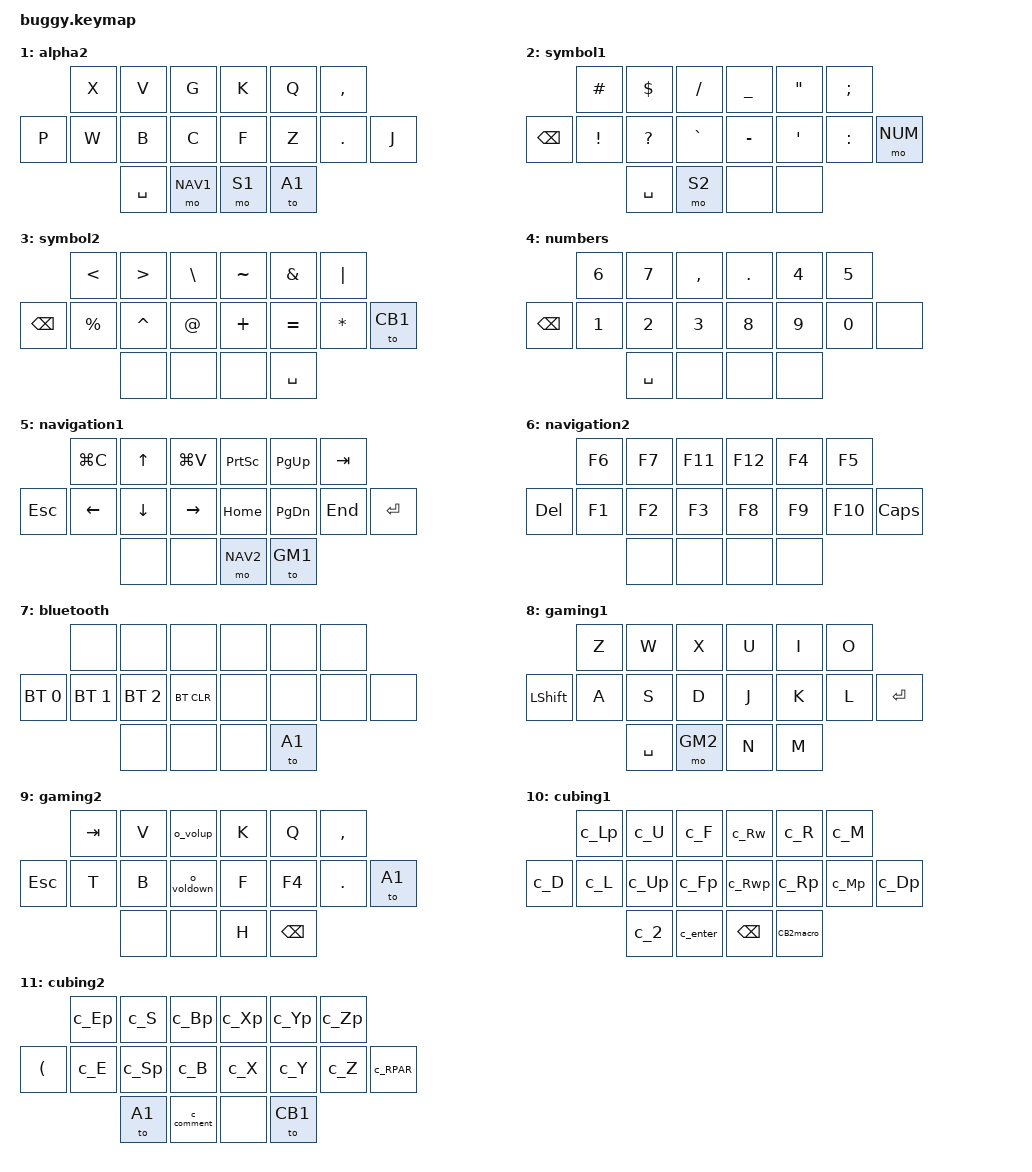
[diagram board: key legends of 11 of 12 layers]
#include <behaviors.dtsi>
#include <dt-bindings/zmk/keys.h>
#include <dt-bindings/zmk/bt.h>

// Homerow Mods
#define hrml(k1,k2,k3,k4) &ht LCTRL k1  &ht LALT k2  &ht LSHFT k3  &ht LCMD k4
#define hrmr(k1,k2,k3,k4) &ht RCMD k1  &ht RSHFT k2  &ht RALT k3  &ht RCTRL k4

#define A1 0
#define A2 1
#define S1 2
#define S2 3
#define NUM 4
#define NAV1 5
#define NAV2 6
#define BT 7
#define GM1 8
#define GM2 9
#define CB1 10
#define CB2 11

//        0  1  2     3  4  5
//     6  7  8  9     10 11 12 13

//           14 15    16 17

/ {
    combos {
        compatible = "zmk,combos";
// a1
        rlcombo {
            timeout-ms = <20>;
            key-positions = <7 0>;
            bindings = <&rlmacro>;
            layers = <A1>;
        };
        tdcombo {
            timeout-ms = <20>;
            key-positions = <8 1>;
            bindings = <&tdmacro>;
            layers = <A1>;
        };
        yscombo {
            timeout-ms = <20>;
            key-positions = <9 2>;
            bindings = <&ysmacro>;
            layers = <A1>;
        };
        hmcombo {
            timeout-ms = <20>;
            key-positions = <10 3>;
            bindings = <&hmmacro>;
            layers = <A1>;
        };
        oacombo {
            timeout-ms = <20>;
            key-positions = <11 4>;
            bindings = <&oamacro>;
            layers = <A1>;
        };
        uicombo {
            timeout-ms = <20>;
            key-positions = <12 5>;
            bindings = <&uimacro>;
            layers = <A1>;
        };
// a2
        ckcombo {
            timeout-ms = <20>;
            key-positions = <9 2>;
            bindings = <&ckmacro>;
            layers = <A2>;
        };
        ffcombo {
            timeout-ms = <20>;
            key-positions = <10 3>;
            bindings = <&ffmacro>;
            layers = <A2>;
        };
        quicombo {
            timeout-ms = <20>;
            key-positions = <11 4>;
            bindings = <&quimacro>;
            layers = <A2>;
        };
        ellicombo {
            timeout-ms = <20>;
            key-positions = <12 5>;
            bindings = <&ellimacro>;
            layers = <A2>;
        };
// s1
        open1combo {
            timeout-ms = <20>;
            key-positions = <7 0>;
            bindings = <&kp LBRC>;
            layers = <S1>;
        };
        open2combo {
            timeout-ms = <20>;
            key-positions = <8 1>;
            bindings = <&kp LPAR>;
            layers = <S1>;
        };
        open3combo {
            timeout-ms = <20>;
            key-positions = <9 2>;
            bindings = <&kp LBKT>;
            layers = <S1>;
        };
        close3combo {
            timeout-ms = <20>;
            key-positions = <10 3>;
            bindings = <&kp RBKT>;
            layers = <S1>;
        };
        close2combo {
            timeout-ms = <20>;
            key-positions = <11 4>;
            bindings = <&kp RPAR>;
            layers = <S1>;
        };
        close1combo {
            timeout-ms = <20>;
            key-positions = <12 5>;
            bindings = <&kp RBRC>;
            layers = <S1>;
        };
        cminicombo {
            timeout-ms = <20>;
            key-positions = <7 8>;
            bindings = <&d_cmini>;
            layers = <S1>;
        };
        codeblockcombo {
            timeout-ms = <20>;
            key-positions = <8 9>;
            bindings = <&d_codeblock>;
            layers = <S1>;
        };
// nav
        btlayercombo {
            timeout-ms = <30>;
            key-positions = <3 4 5>;
            bindings = <&to BT>;
            layers = <NAV1>;
        };
        savecombo {
            timeout-ms = <20>;
            key-positions = <10 11>;
            bindings = <&v_save>;
            layers = <NAV1>;
        };
        exitcombo {
            timeout-ms = <20>;
            key-positions = <11 12>;
            bindings = <&v_exit>;
            layers = <NAV1>;
        };

    };

    behaviors {
        ht: hold_tap {
            compatible = "zmk,behavior-hold-tap";
            label = "hold_tap";
            #binding-cells = <2>;
            flavor = "tap-preferred";
            tapping-term-ms = <190>;
            quick-tap-ms = <125>;
            global-quick-tap;
            bindings = <&kp>, <&kp>;
        };
        A2macro: A2macro {
		    compatible = "zmk,behavior-macro";
		    label = "A2macro";
	    	#binding-cells = <0>;
	    	bindings = <&sl A2>;
        };
        CB2macro: CB2macro {
		    compatible = "zmk,behavior-macro";
		    label = "CB2macro";
	    	#binding-cells = <0>;
	    	bindings = <&sl CB2>;
        };
// a1
        rlmacro: rlmacro {
            compatible = "zmk,behavior-macro";
            label = "rlmacro";
            #binding-cells = <0>;
            wait-ms = <0>;
            bindings = <&kp R &kp L>;
        };
        tdmacro: tdmacro {
            compatible = "zmk,behavior-macro";
            label = "tdmacro";
            #binding-cells = <0>;
            wait-ms = <0>;
            bindings = <&kp T &kp D>;
        };
        ysmacro: ysmacro {
            compatible = "zmk,behavior-macro";
            label = "ysmacro";
            #binding-cells = <0>;
            wait-ms = <0>;
            bindings = <&kp Y &kp S>;
        };
        hmmacro: hmmacro {
            compatible = "zmk,behavior-macro";
            label = "hmmacro";
            #binding-cells = <0>;
            wait-ms = <0>;
            bindings = <&kp H &kp M>;
        };
        oamacro: oamacro {
            compatible = "zmk,behavior-macro";
            label = "oamacro";
            #binding-cells = <0>;
            wait-ms = <0>;
            bindings = <&kp O &kp A>;
        };
        uimacro: uimacro {
            compatible = "zmk,behavior-macro";
            label = "uimacro";
            #binding-cells = <0>;
            wait-ms = <0>;
            bindings = <&kp U &kp I>;
        };
// a2
        ckmacro: ckmacro {
            compatible = "zmk,behavior-macro";
            label = "ckmacro";
            #binding-cells = <0>;
            wait-ms = <0>;
            bindings = <&kp C &kp K>;
        };
        ffmacro: ffmacro {
            compatible = "zmk,behavior-macro";
            label = "ffmacro";
            #binding-cells = <0>;
            wait-ms = <0>;
            bindings = <&kp F &kp F>;
        };
        quimacro: quimacro {
            compatible = "zmk,behavior-macro";
            label = "quimacro";
            #binding-cells = <0>;
            wait-ms = <0>;
            bindings = <&kp Q &kp U &kp I>;
        };
        ellimacro: ellimacro {
            compatible = "zmk,behavior-macro";
            label = "ellimacro";
            #binding-cells = <0>;
            wait-ms = <0>;
            bindings = <&kp DOT &kp DOT &kp DOT>;
        };
// cubing
        c_D: c_D {
            compatible = "zmk,behavior-macro";
            label = "c_D";
            #binding-cells = <0>;
            wait-ms = <0>;
            bindings
                = <&macro_press &kp LSHFT>
                , <&macro_tap &kp D>
                , <&macro_release &kp LSHFT>
                , <&macro_tap &kp SPACE>
                ;
        };
        c_L: c_L {
            compatible = "zmk,behavior-macro";
            label = "c_L";
            #binding-cells = <0>;
            wait-ms = <0>;
            bindings
                = <&macro_press &kp LSHFT>
                , <&macro_tap &kp L>
                , <&macro_release &kp LSHFT>
                , <&macro_tap &kp SPACE>
                ;
        };
        c_Lp: c_Lp {
            compatible = "zmk,behavior-macro";
            label = "c_Lp";
            #binding-cells = <0>;
            wait-ms = <0>;
            bindings
                = <&macro_press &kp LSHFT>
                , <&macro_tap &kp L>
                , <&macro_release &kp LSHFT>
                , <&macro_tap &kp SQT>
                , <&macro_tap &kp SPACE>
                ;
        };
        c_Up: c_Up {
            compatible = "zmk,behavior-macro";
            label = "c_Up";
            #binding-cells = <0>;
            wait-ms = <0>;
            bindings
                = <&macro_press &kp LSHFT>
                , <&macro_tap &kp U>
                , <&macro_release &kp LSHFT>
                , <&macro_tap &kp SQT>
                , <&macro_tap &kp SPACE>
                ;
        };
        c_U: c_U {
            compatible = "zmk,behavior-macro";
            label = "c_U";
            #binding-cells = <0>;
            wait-ms = <0>;
            bindings
                = <&macro_press &kp LSHFT>
                , <&macro_tap &kp U>
                , <&macro_release &kp LSHFT>
                , <&macro_tap &kp SPACE>
                ;
        };
        c_Fp: c_Fp {
            compatible = "zmk,behavior-macro";
            label = "c_Fp";
            #binding-cells = <0>;
            wait-ms = <0>;
            bindings
                = <&macro_press &kp LSHFT>
                , <&macro_tap &kp F>
                , <&macro_release &kp LSHFT>
                , <&macro_tap &kp SQT>
                , <&macro_tap &kp SPACE>
                ;
        };
        c_F: c_F {
            compatible = "zmk,behavior-macro";
            label = "c_F";
            #binding-cells = <0>;
            wait-ms = <0>;
            bindings
                = <&macro_press &kp LSHFT>
                , <&macro_tap &kp F>
                , <&macro_release &kp LSHFT>
                , <&macro_tap &kp SPACE>
                ;
        };
        c_Rwp: c_Rwp {
            compatible = "zmk,behavior-macro";
            label = "c_Rwp";
            #binding-cells = <0>;
            wait-ms = <0>;
            bindings
                = <&macro_tap &kp R &kp SQT &kp SPACE>
                ;
        };
        c_Rw: c_Rw {
            compatible = "zmk,behavior-macro";
            label = "c_Rw";
            #binding-cells = <0>;
            wait-ms = <0>;
            bindings
                = <&macro_tap &kp R &kp SPACE>
                ;
        };
        c_Rp: c_Rp {
            compatible = "zmk,behavior-macro";
            label = "c_Rp";
            #binding-cells = <0>;
            wait-ms = <0>;
            bindings
                = <&macro_press &kp LSHFT>
                , <&macro_tap &kp R>
                , <&macro_release &kp LSHFT>
                , <&macro_tap &kp SQT>
                , <&macro_tap &kp SPACE>
                ;
        };
        c_R: c_R {
            compatible = "zmk,behavior-macro";
            label = "c_R";
            #binding-cells = <0>;
            wait-ms = <0>;
            bindings
                = <&macro_press &kp LSHFT>
                , <&macro_tap &kp R>
                , <&macro_release &kp LSHFT>
                , <&macro_tap &kp SPACE>
                ;
        };
        c_Mp: c_Mp {
            compatible = "zmk,behavior-macro";
            label = "c_Mp";
            #binding-cells = <0>;
            wait-ms = <0>;
            bindings
                = <&macro_press &kp LSHFT>
                , <&macro_tap &kp M>
                , <&macro_release &kp LSHFT>
                , <&macro_tap &kp SQT>
                , <&macro_tap &kp SPACE>
                ;
        };
        c_M: c_M {
            compatible = "zmk,behavior-macro";
            label = "c_M";
            #binding-cells = <0>;
            wait-ms = <0>;
            bindings
                = <&macro_press &kp LSHFT>
                , <&macro_tap &kp M>
                , <&macro_release &kp LSHFT>
                , <&macro_tap &kp SPACE>
                ;
        };
        c_Dp: c_Dp {
            compatible = "zmk,behavior-macro";
            label = "c_Dp";
            #binding-cells = <0>;
            wait-ms = <0>;
            bindings
                = <&macro_press &kp LSHFT>
                , <&macro_tap &kp D>
                , <&macro_release &kp LSHFT>
                , <&macro_tap &kp SQT>
                , <&macro_tap &kp SPACE>
                ;
        };
        c_2: c_2 {
            compatible = "zmk,behavior-macro";
            label = "c_2";
            #binding-cells = <0>;
            wait-ms = <0>;
            bindings
                = <&macro_tap &kp BSPC &kp N2 &kp SPACE>
                ;
        };
        c_enter: c_enter {
            compatible = "zmk,behavior-macro";
            label = "c_enter";
            #binding-cells = <0>;
            wait-ms = <0>;
            bindings
                = <&macro_tap &kp BSPC>
                , <&macro_press &kp LSHFT>
                , <&macro_tap &kp RET>
                , <&macro_release &kp LSHFT>
                ;
        };
        c_E: c_E {
            compatible = "zmk,behavior-macro";
            label = "c_E";
            #binding-cells = <0>;
            wait-ms = <0>;
            bindings
                = <&macro_press &kp LSHFT>
                , <&macro_tap &kp E>
                , <&macro_release &kp LSHFT>
                , <&macro_tap &kp SPACE>
                ;
        };
        c_Ep: c_Ep {
            compatible = "zmk,behavior-macro";
            label = "c_Ep";
            #binding-cells = <0>;
            wait-ms = <0>;
            bindings
                = <&macro_press &kp LSHFT>
                , <&macro_tap &kp E>
                , <&macro_release &kp LSHFT>
                , <&macro_tap &kp SQT>
                , <&macro_tap &kp SPACE>
                ;
        };
        c_Sp: c_Sp {
            compatible = "zmk,behavior-macro";
            label = "c_Sp";
            #binding-cells = <0>;
            wait-ms = <0>;
            bindings
                = <&macro_press &kp LSHFT>
                , <&macro_tap &kp S>
                , <&macro_release &kp LSHFT>
                , <&macro_tap &kp SQT>
                , <&macro_tap &kp SPACE>
                ;
        };
        c_S: c_S {
            compatible = "zmk,behavior-macro";
            label = "c_S";
            #binding-cells = <0>;
            wait-ms = <0>;
            bindings
                = <&macro_press &kp LSHFT>
                , <&macro_tap &kp S>
                , <&macro_release &kp LSHFT>
                , <&macro_tap &kp SPACE>
                ;
        };
        c_B: c_B {
            compatible = "zmk,behavior-macro";
            label = "c_B";
            #binding-cells = <0>;
            wait-ms = <0>;
            bindings
                = <&macro_press &kp LSHFT>
                , <&macro_tap &kp B>
                , <&macro_release &kp LSHFT>
                , <&macro_tap &kp SPACE>
                ;
        };
        c_Bp: c_Bp {
            compatible = "zmk,behavior-macro";
            label = "c_Bp";
            #binding-cells = <0>;
            wait-ms = <0>;
            bindings
                = <&macro_press &kp LSHFT>
                , <&macro_tap &kp B>
                , <&macro_release &kp LSHFT>
                , <&macro_tap &kp SQT>
                , <&macro_tap &kp SPACE>
                ;
        };
        c_X: c_X {
            compatible = "zmk,behavior-macro";
            label = "c_X";
            #binding-cells = <0>;
            wait-ms = <0>;
            bindings
                = <&macro_tap &kp X &kp SPACE>
                ;
        };
        c_Xp: c_Xp {
            compatible = "zmk,behavior-macro";
            label = "c_Xp";
            #binding-cells = <0>;
            wait-ms = <0>;
            bindings
                = <&macro_tap &kp X &kp SQT &kp SPACE>
                ;
        };
        c_Y: c_Y {
            compatible = "zmk,behavior-macro";
            label = "c_Y";
            #binding-cells = <0>;
            wait-ms = <0>;
            bindings
                = <&macro_tap &kp Y &kp SPACE>
                ;
        };
        c_Yp: c_Yp {
            compatible = "zmk,behavior-macro";
            label = "c_Yp";
            #binding-cells = <0>;
            wait-ms = <0>;
            bindings
                = <&macro_tap &kp Y &kp SQT &kp SPACE>
                ;
        };
        c_Z: c_Z {
            compatible = "zmk,behavior-macro";
            label = "c_Z";
            #binding-cells = <0>;
            wait-ms = <0>;
            bindings
                = <&macro_tap &kp Z &kp SPACE>
                ;
        };
        c_Zp: c_Zp {
            compatible = "zmk,behavior-macro";
            label = "c_Zp";
            #binding-cells = <0>;
            wait-ms = <0>;
            bindings
                = <&macro_tap &kp Z &kp SQT &kp SPACE>
                ;
        };
        c_RPAR: c_RPAR {
            compatible = "zmk,behavior-macro";
            label = "c_RPAR";
            #binding-cells = <0>;
            wait-ms = <0>;
            bindings
                = <&macro_tap &kp BSPC &kp RPAR &kp SPACE>
                ;
        };
        c_comment: c_comment {
            compatible = "zmk,behavior-macro";
            label = "c_comment";
            #binding-cells = <0>;
            wait-ms = <0>;
            bindings
                = <&macro_tap &kp FSLH &kp FSLH &kp SPACE &to A1>
                ;
        };
// discord
        d_codeblock: d_codeblock {
            compatible = "zmk,behavior-macro";
            label = "d_codeblock";
            #binding-cells = <0>;
            wait-ms = <0>;
            bindings
                = <&macro_tap
                    &kp GRAVE &kp GRAVE &kp GRAVE
                    &kp RET &kp RET
                    &kp GRAVE &kp GRAVE &kp GRAVE
                    &kp UP
                    >
                ;
        };
        d_cmini: d_cmini {
            compatible = "zmk,behavior-macro";
            label = "d_cmini";
            #binding-cells = <0>;
            wait-ms = <0>;
            bindings
                = <&macro_tap
                    &kp EXCL
                    &kp C &kp M &kp I &kp N &kp I
                    &kp SPACE
                    >
                ;
        };
// vim
        v_save: v_save {
            compatible = "zmk,behavior-macro";
            label = "v_save";
            #binding-cells = <0>;
            wait-ms = <0>;
            bindings
                = <&macro_tap &kp COLON &kp W &kp RET>
                ;
        };
        v_exit: v_exit {
            compatible = "zmk,behavior-macro";
            label = "v_exit";
            #binding-cells = <0>;
            wait-ms = <0>;
            bindings
                = <&macro_tap &kp COLON &kp Q &kp RET>
                ;
        };
// osu
        o_volup: o_volup {
            compatible = "zmk,behavior-macro";
            label = "o_volup";
            #binding-cells = <0>;
            wait-ms = <0>;
            bindings
                = <&macro_press &kp LALT>
                , <&macro_tap &kp UP>
                , <&macro_release &kp LALT>
                ;
        };
        o_voldown: o_voldown {
            compatible = "zmk,behavior-macro";
            label = "o_voldown";
            #binding-cells = <0>;
            wait-ms = <0>;
            bindings
                = <&macro_press &kp LALT>
                , <&macro_tap &kp DOWN>
                , <&macro_release &kp LALT>
                ;
        };


    };

    keymap {
        compatible = "zmk,keymap";

        alpha1 {
            bindings = <
                            &kp L       &kp D       &kp Y               &kp M       &kp O       &kp U
               hrml(N,          R,          T,          S)             hrmr(H,          A,          I,          E)

                                        &kp SPACE   &mo NAV1            &mo S1      &A2macro
            >;
        };

        alpha2 {
            bindings = <
                            &kp X       &kp V       &kp G               &kp K       &kp Q       &kp COMMA
                &kp P       &kp W       &kp B       &kp C               &kp F       &kp Z       &kp DOT     &kp J

                                        &kp SPACE   &mo NAV1            &mo S1      &to A1
            >;
        };

        symbol1 {
            bindings = <
                            &kp HASH    &kp DLLR    &kp FSLH            &kp UNDER   &kp DQT     &kp SEMI
                &kp BSPC    &kp EXCL    &kp QMARK   &kp GRAVE           &kp MINUS   &kp SQT     &kp COLON   &mo NUM

                                        &kp SPACE   &mo S2              &none       &none
            >;
        };

        symbol2 {
            bindings = <
                            &kp LT      &kp GT      &kp BSLH            &kp TILDE   &kp AMPS    &kp PIPE
                &kp BSPC    &kp PRCNT   &kp CARET   &kp AT              &kp PLUS    &kp EQUAL   &kp STAR    &to CB1

                                        &none       &none               &none       &kp SPACE
            >;
        };

        numbers {
            bindings = <
                            &kp N6      &kp N7      &kp COMMA           &kp DOT     &kp N4      &kp N5
                &kp BSPC    &kp N1      &kp N2      &kp N3              &kp N8      &kp N9      &kp N0      &none

                                        &kp SPACE   &none               &none       &none
            >;
        };

        navigation1 {
            bindings = <
                            &kp LG(C)   &kp UP      &kp LG(V)           &kp PSCRN   &kp PG_UP   &kp TAB
                &kp ESC     &kp LEFT    &kp DOWN    &kp RIGHT           &kp HOME    &kp PG_DN   &kp END     &kp RET

                                        &none       &none               &mo NAV2    &to GM1
            >;
        };

        navigation2 {
            bindings = <
                            &kp F6      &kp F7      &kp F11             &kp F12     &kp F4      &kp F5
                &kp DEL     &kp F1      &kp F2      &kp F3              &kp F8      &kp F9      &kp F10     &kp CAPS

                                        &none       &none               &none       &none
            >;
        };

        bluetooth {
            bindings = <
                            &none       &none       &none               &none       &none       &none
                &bt BT_SEL 0 &bt BT_SEL 1 &bt BT_SEL 2 &bt BT_CLR       &none       &none       &none       &none

                                        &none       &none               &none       &to A1
            >;
        };

        gaming1 {
            bindings = <
                            &kp Z       &kp W       &kp X               &kp U       &kp I       &kp O
                &kp LSHIFT  &kp A       &kp S       &kp D               &kp J       &kp K       &kp L       &kp ENTER

                                        &kp SPACE   &mo GM2             &kp N       &kp M
            >;
        };

        gaming2 {
            bindings = <
                            &kp TAB     &kp V       &o_volup            &kp K       &kp Q       &kp COMMA
                &kp ESC     &kp T       &kp B       &o_voldown          &kp F       &kp F4      &kp DOT     &to A1

                                        &none       &none               &kp H       &kp BSPC
            >;
        };

        cubing1 {
            bindings = <
                            &c_Lp       &c_U        &c_F                &c_Rw       &c_R        &c_M
                &c_D        &c_L        &c_Up       &c_Fp               &c_Rwp      &c_Rp       &c_Mp     &c_Dp

                                        &c_2        &c_enter            &kp BSPC    &CB2macro
            >;
        };

        cubing2 {
            bindings = <
                            &c_Ep       &c_S        &c_Bp               &c_Xp       &c_Yp       &c_Zp
                &kp LPAR    &c_E        &c_Sp       &c_B                &c_X        &c_Y        &c_Z      &c_RPAR

                                        &to A1      &c_comment          &none       &to CB1
            >;
        };

    };
};
